VERSION ""

NS_ :

BS_: 500

BU_: Vector__XXX

BO_ 194 MSG_0C2: 6 Vector__XXX
 SG_ Steering_Angle : 48|16@0+ (0.1,-3276.7) [0|0] "" Vector__XXX

BO_ 385 MSG_181: 8 Vector__XXX
 SG_ Throttle_Position : 32|8@0+ (0.423,-6.768) [0|100] "%" Vector__XXX
 SG_ Engine_Speed : 48|16@0+ (0.125,0) [0|10000] "rpm" Vector__XXX

BO_ 505 MSG_1F9: 6 Vector__XXX
 SG_ Ignition___Starter_Position : 60|1@0+ (1,0) [0|0] "" Vector__XXX

BO_ 644 MSG_284: 8 Vector__XXX
 SG_ Indicated_Vehicle_Speed_kph : 16|16@0+ (0.01,0) [0|655.35] "km/h" Vector__XXX
 SG_ Indicated_Vehicle_Speed_mph : 16|16@0+ (0.00621,0) [0|406.97235] "mph" Vector__XXX
 SG_ Wheel_Speed_FL_kph : 32|16@0+ (0.00541,0) [0|354.54435] "km/h" Vector__XXX
 SG_ Wheel_Speed_FL_mph : 32|16@0+ (0.00335961,0) [0|220.17204135] "mph" Vector__XXX
 SG_ Wheel_Speed_FR_kph : 48|16@0+ (0.00541,0) [0|354.54435] "km/h" Vector__XXX
 SG_ Wheel_Speed_FR_mph : 48|16@0+ (0.00335961,0) [0|220.17204135] "mph" Vector__XXX

BO_ 645 MSG_285: 8 Vector__XXX
 SG_ Wheel_Speed_RL_kph : 32|16@0+ (0.00537,0) [0|351.92295] "km/h" Vector__XXX
 SG_ Wheel_Speed_RL_mph : 32|16@0+ (0.00333477,0) [0|218.54415195] "mph" Vector__XXX
 SG_ Wheel_Speed_RR_kph : 48|16@0+ (0.00537,0) [0|351.92295] "km/h" Vector__XXX
 SG_ Wheel_Speed_RR_mph : 48|16@0+ (0.00333477,0) [0|218.54415195] "mph" Vector__XXX

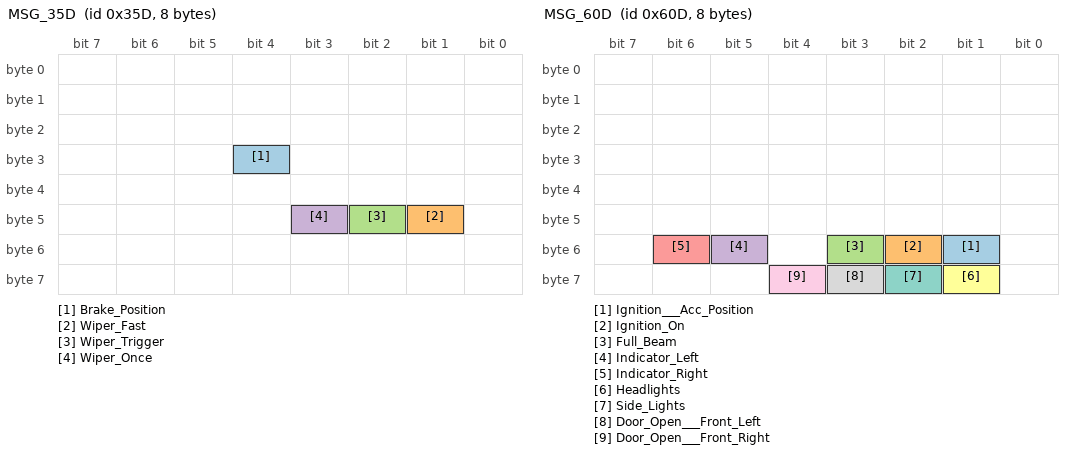
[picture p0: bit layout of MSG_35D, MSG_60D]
BO_ 861 MSG_35D: 8 Vector__XXX
 SG_ Brake_Position : 28|1@0+ (1,0) [0|0] "" Vector__XXX
 SG_ Wiper_Fast : 41|1@0+ (1,0) [0|0] "" Vector__XXX
 SG_ Wiper_Trigger : 42|1@0+ (1,0) [0|0] "" Vector__XXX
 SG_ Wiper_Once : 43|1@0+ (1,0) [0|0] "" Vector__XXX

BO_ 1361 MSG_551: 7 Vector__XXX
 SG_ Fuel_Consumption : 8|8@1+ (1,0) [0|0] "mm��" Vector__XXX
 SG_ Coolant_Temperature : 56|8@0+ (1,-50) [-50|205] "��C" Vector__XXX

BO_ 1477 MSG_5C5: 8 Vector__XXX
 SG_ Handbrake : 58|1@0+ (1,0) [0|0] "" Vector__XXX

BO_ 1549 MSG_60D: 8 Vector__XXX
 SG_ Ignition___Acc_Position : 49|1@0+ (1,0) [0|0] "" Vector__XXX
 SG_ Ignition_On : 50|1@0+ (1,0) [0|0] "" Vector__XXX
 SG_ Full_Beam : 51|1@0+ (1,0) [0|0] "" Vector__XXX
 SG_ Indicator_Left : 53|1@0+ (1,0) [0|0] "" Vector__XXX
 SG_ Indicator_Right : 54|1@0+ (1,0) [0|0] "" Vector__XXX
 SG_ Headlights : 57|1@0+ (1,0) [0|0] "" Vector__XXX
 SG_ Side_Lights : 58|1@0+ (1,0) [0|0] "" Vector__XXX
 SG_ Door_Open___Front_Left : 59|1@0+ (1,0) [0|0] "" Vector__XXX
 SG_ Door_Open___Front_Right : 60|1@0+ (1,0) [0|0] "" Vector__XXX
